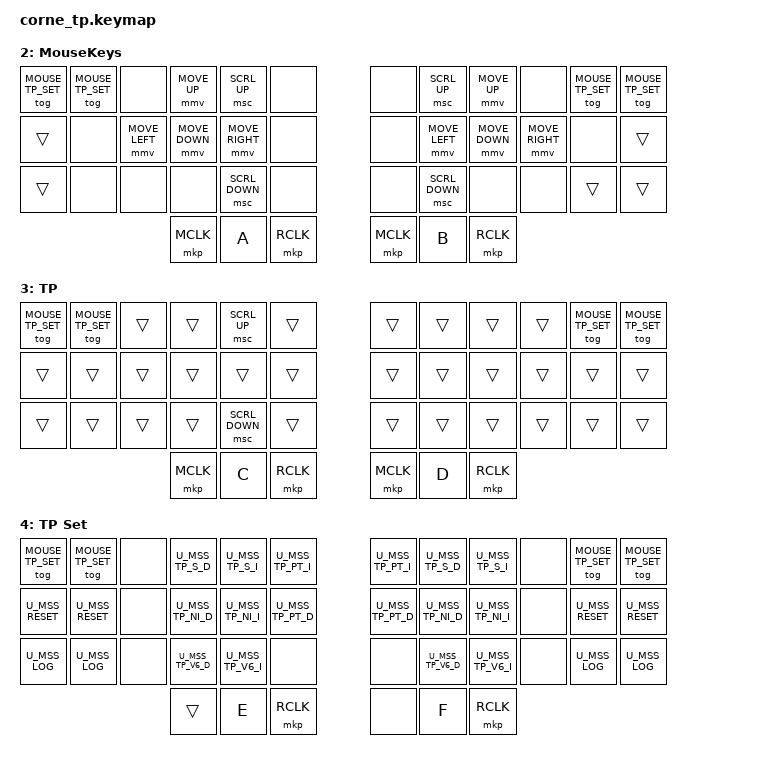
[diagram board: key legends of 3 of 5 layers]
#include <behaviors.dtsi>
#include <dt-bindings/zmk/keys.h>
#include <dt-bindings/zmk/bt.h>

#define BASE 0
#define LOWER 1
#define MOUSE_KEYS 2
#define MOUSE_TP 3
#define MOUSE_TP_SET 4


/*
 * Defines to enable/disable features
 *
 * These defines allow us to conditionally enable and disable parts of the keymap config.
 *
 * For example, if we decide to build the firmware without the mouse features, we can
 * disable all the config options that rely on those forks and modules without having
 * to edit the entire keymap file manually every time.
 */

#define HAS_MOUSE_KEYS
#define HAS_MOUSE_TP

#ifdef HAS_MOUSE_KEYS
  #include <dt-bindings/zmk/mouse.h>
  #include <behaviors/mouse_keys.dtsi>
#endif  // HAS_MOUSE_KEYS

#ifdef HAS_MOUSE_TP
  // We store the trackpoint settings in a separate file
  // to make organization a little easier.
  #include "include/mouse_tp.dtsi"
#endif  // HAS_MOUSE_TP



// Adjust layer keys based on enabled features.
//
// This prevents build errors when we build the firmware
// without the mouse keys PR or the TP module.
#ifdef HAS_MOUSE_KEYS
  #define U_THUMB_INNER &mo MOUSE_KEYS
#else
  #define U_THUMB_INNER &none
#endif  // HAS_MOUSE_KEYS

#ifdef HAS_MOUSE_TP
  #define U_TOG_TP_SET &tog MOUSE_TP_SET
#else
  #define U_TOG_TP_SET &none
#endif  // HAS_MOUSE_TP




/ {
    keymap {
        compatible = "zmk,keymap";

        default_layer { // Layer 0 - Main layer
            bindings = <
            // Row 0: Back-Tick, F1, F2, 5, 6, Equal, F8, Minus, F9, Insert, Delete, Page-Up, Home, , , Ctrl-L
                &kp GRAVE  &kp F1   &kp F2   &kp N5   &kp N6   &kp EQUAL &kp F8   &kp MINUS &kp F9   &kp INS   &kp DEL   &kp PG_UP &kp HOME               &kp LCTRL
            // Row 1: 1, 2, 3, 4, 7, 8, 9, 0, F10, F12, F11, Page-Down, End, Print-Screen
                &kp N1     &kp N2   &kp N3   &kp N4   &kp N7   &kp N8    &kp N9   &kp N0    &kp F10  &kp F12   &kp F11   &kp PG_DN &kp END  &kp PSCRN
            // Row 2: Q, W, E, R, U, I, O, P, VolumeUp, GUI, ScrollLock
                &kp Q      &kp W    &kp E    &kp R    &kp U    &kp I     &kp O    &kp P              &kp C_VOL_UP &kp LGUI    &kp SLCK
            // Row 3: Tab, CapsLock, F3, T, Y, Right-Brace, F7, Left-Brace, Back-Space, VolumeDown, Shift-L
                &kp TAB    &kp CAPS &kp F3   &kp T    &kp Y    &kp RBKT  &kp F7   &kp LBKT  &kp BSPC   &kp C_VOL_DN            &kp LSHFT
            // Row 4: A, S, D, F, J, K, L, Semi-colon, Back-Slash, Mute, Menu
                &kp A      &kp S    &kp D    &kp F    &kp J    &kp K     &kp L    &kp SEMI  &kp BSLH    &kp C_MUTE &kp K_CMENU
            // Row 5: Esc, F4, G, H, F6, Quote, F5, Think-Vantage, Arrow-Up, Alt-L
                &bootloader       &kp F4   &kp G    &kp H    &kp F6           &kp SQT   &kp F5      &kp A      &kp UP    &kp LALT
            // Row 6: Z, X, C, V, M, Comma, Period, Forward-Slash, Enter, PageLeft, Pause, Shift-R, Ctrl-R
                &kp Z      &kp X    &kp C    &kp V    &kp M    &kp COMMA &kp DOT  &kp FSLH  &kp RET        &kp C_AC_BACK &kp PAUSE_BREAK    &kp RSHFT &kp RCTRL
            // Row 7: B, N, Forward-Slash, Space, Arrow-Right, ArrowDown, Page-Right, Arrow-Left, Alt-R
                            &kp B    &kp N       &kp FSLH &kp SPACE &kp RIGHT &kp DOWN &kp C_AC_FORWARD &kp LEFT &kp RALT
            // Row 8 (NEW): FN_KEY, POWER_KEY
                &mo 1  &kp B
            >;
        };

        bt_layer { // Layer 1 - Bluetooth and system controls
            bindings = <
            // Row 0: System controls
                &none &bt BT_CLR &sys_reset U_MSS_TP_V6_I   U_MSS_TP_V6_D    &none     &none    &none     &none    &none     &none     &bootloader     &none                &none
            // Row 1: Bluetooth selection
                &bt BT_SEL 0 &bt BT_SEL 1 &bt BT_SEL 2 &bt BT_SEL 3 &bt BT_SEL 4 U_MSS_TP_S_I U_MSS_TP_S_D &none &none &none &none &none &none &none
            // Row 2-7: Pass through or none
                &none      &none    &none    &none    &none    &none     &none    &none              &none        &none       &none
                &none      &none    &none    &none    &none    &none     &none    &none     &none      &none                   &none
                &none      &none    &none    &none    &none    &none     &none    &none     &none    &none        &none       &none
                &none             &none    &none    &none    &none             &none     &none        &none        &none       &none
                &none      &none    &none    &none    &none    &none     &none    &none     &none        &none       &none          &none &none
                            &none    &none       &none    &none     &none     &none     &none        &none       &none
            // Row 8 (NEW): placeholders to match RC(8,0) / RC(8,1)
                &none  &none
            >;
        };



        #ifdef HAS_MOUSE_KEYS

            MouseKeys_layer {
            display-name = "MouseKeys";
            bindings = <
        // ╭────────────────────────┬────────────────────────┬────────────────────────┬────────────────────────┬────────────────────────┬────────────────────────╮    ╭────────────────────────┬────────────────────────┬────────────────────────┬────────────────────────┬────────────────────────┬────────────────────────╮
            U_TOG_TP_SET             U_TOG_TP_SET             &none                    &mmv MOVE_UP             &msc SCRL_UP             &none                         &none                    &msc SCRL_UP             &mmv MOVE_UP             &none                    U_TOG_TP_SET              U_TOG_TP_SET
        // ├────────────────────────┼────────────────────────┼────────────────────────┼────────────────────────┼────────────────────────┼────────────────────────┤    ├────────────────────────┼────────────────────────┼────────────────────────┼────────────────────────┼────────────────────────┼────────────────────────┤
            &trans                   &none                    &mmv MOVE_LEFT           &mmv MOVE_DOWN           &mmv MOVE_RIGHT          &none                         &none                    &mmv MOVE_LEFT           &mmv MOVE_DOWN           &mmv MOVE_RIGHT          &none                     &trans
        // ├────────────────────────┼────────────────────────┼────────────────────────┼────────────────────────┼────────────────────────┼────────────────────────┤    ├────────────────────────┼────────────────────────┼────────────────────────┼────────────────────────┼────────────────────────┼────────────────────────┤
            &trans                   &none                    &none                    &none                    &msc SCRL_DOWN           &none                         &none                    &msc SCRL_DOWN           &none                    &none                    &trans                    &trans
        // ╰────────────────────────┴────────────────────────┴────────────────────────┴────────────────────────┼────────────────────────┼────────────────────────┤    ├────────────────────────┼────────────────────────┼────────────────────────┼────────────────────────┴────────────────────────┼────────────────────────╯
                                                                                        &mkp MCLK                &kp A                &mkp RCLK                     &mkp MCLK                &kp B                &mkp RCLK
        //                                                                            ╰────────────────────────┴────────────────────────┴────────────────────────╯    ╰────────────────────────┴────────────────────────┴────────────────────────╯

    >;
            };

        #endif

        #ifdef HAS_MOUSE_TP

            // Automatically activated when the mouse or trackpoint moves.
            // Configured in `include/mouse_tp.dtsi`.
            MouseTP_layer {
            display-name = "TP";
            bindings = <
        // ╭────────────────────────┬────────────────────────┬────────────────────────┬────────────────────────┬────────────────────────┬────────────────────────╮    ╭────────────────────────┬────────────────────────┬────────────────────────┬────────────────────────┬────────────────────────┬────────────────────────╮
            U_TOG_TP_SET             U_TOG_TP_SET             &trans                   &trans                   &msc SCRL_UP             &trans                        &trans                   &trans                   &trans                   &trans                   U_TOG_TP_SET              U_TOG_TP_SET
        // ├────────────────────────┼────────────────────────┼────────────────────────┼────────────────────────┼────────────────────────┼────────────────────────┤    ├────────────────────────┼────────────────────────┼────────────────────────┼────────────────────────┼────────────────────────┼────────────────────────┤
            &trans                   &trans                   &trans                   &trans                   &trans                   &trans                        &trans                   &trans                   &trans                   &trans                   &trans                    &trans
        // ├────────────────────────┼────────────────────────┼────────────────────────┼────────────────────────┼────────────────────────┼────────────────────────┤    ├────────────────────────┼────────────────────────┼────────────────────────┼────────────────────────┼────────────────────────┼────────────────────────┤
            &trans                   &trans                   &trans                   &trans                   &msc SCRL_DOWN           &trans                        &trans                   &trans                   &trans                   &trans                   &trans                    &trans
        // ╰────────────────────────┴────────────────────────┴────────────────────────┴────────────────────────┼────────────────────────┼────────────────────────┤    ├────────────────────────┼────────────────────────┼────────────────────────┼────────────────────────┴────────────────────────┼────────────────────────╯
                                                                                        &mkp MCLK                &kp C                &mkp RCLK                     &mkp MCLK                &kp D                &mkp RCLK
        //                                                                            ╰────────────────────────┴────────────────────────┴────────────────────────╯    ╰────────────────────────┴────────────────────────┴────────────────────────╯

            >;
            };

            // You can find the defines for the actual key press behaviors in `include/mouse_tp.dtsi`.
            MouseSettings_layer {
            display-name = "TP Set";
            bindings = <
        // ╭────────────────────────┬────────────────────────┬────────────────────────┬────────────────────────┬────────────────────────┬────────────────────────╮    ╭────────────────────────┬────────────────────────┬────────────────────────┬────────────────────────┬────────────────────────┬────────────────────────╮
            U_TOG_TP_SET             U_TOG_TP_SET             &none                    U_MSS_TP_S_D             U_MSS_TP_S_I             U_MSS_TP_PT_I                 U_MSS_TP_PT_I            U_MSS_TP_S_D             U_MSS_TP_S_I             &none                    U_TOG_TP_SET              U_TOG_TP_SET
        // ├────────────────────────┼────────────────────────┼────────────────────────┼────────────────────────┼────────────────────────┼────────────────────────┤    ├────────────────────────┼────────────────────────┼────────────────────────┼────────────────────────┼────────────────────────┼────────────────────────┤
            U_MSS_RESET              U_MSS_RESET              &none                    U_MSS_TP_NI_D            U_MSS_TP_NI_I            U_MSS_TP_PT_D                 U_MSS_TP_PT_D            U_MSS_TP_NI_D            U_MSS_TP_NI_I            &none                    U_MSS_RESET               U_MSS_RESET
        // ├────────────────────────┼────────────────────────┼────────────────────────┼────────────────────────┼────────────────────────┼────────────────────────┤    ├────────────────────────┼────────────────────────┼────────────────────────┼────────────────────────┼────────────────────────┼────────────────────────┤
            U_MSS_LOG                U_MSS_LOG                &none                    U_MSS_TP_V6_D            U_MSS_TP_V6_I            &none                         &none                    U_MSS_TP_V6_D            U_MSS_TP_V6_I            &none                    U_MSS_LOG                 U_MSS_LOG
        // ╰────────────────────────┴────────────────────────┴────────────────────────┴────────────────────────┼────────────────────────┼────────────────────────┤    ├────────────────────────┼────────────────────────┼────────────────────────┼────────────────────────┴────────────────────────┼────────────────────────╯
                                                                                        &trans                   &kp E                &mkp RCLK                     &none                    &kp F                &mkp RCLK
        //                                                                            ╰────────────────────────┴────────────────────────┴────────────────────────╯    ╰────────────────────────┴────────────────────────┴────────────────────────╯

            >;
            };

        #endif
    };
};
